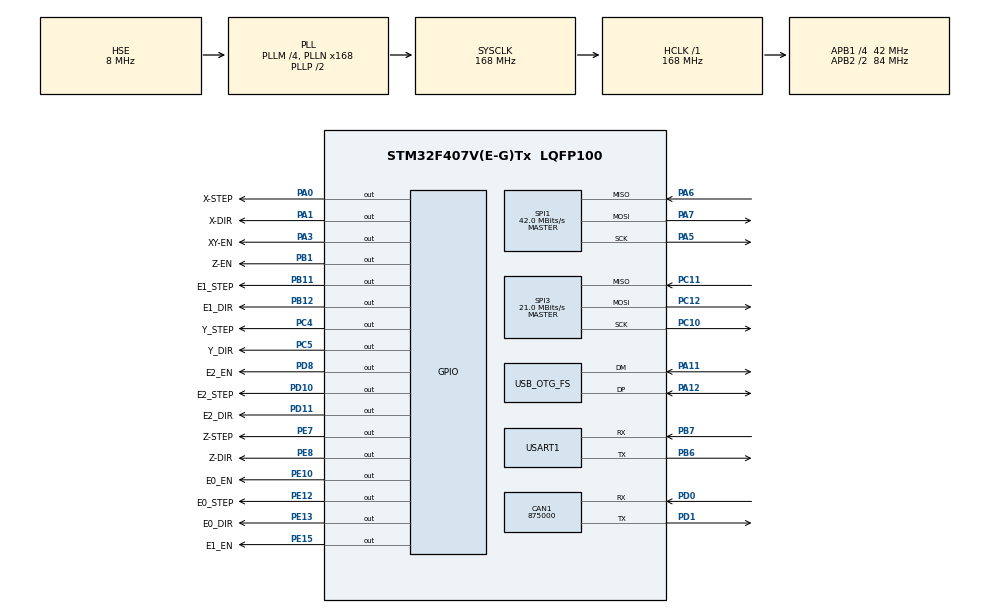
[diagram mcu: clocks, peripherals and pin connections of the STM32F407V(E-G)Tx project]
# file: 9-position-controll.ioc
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CAN1.CalculateBaudRate=875000
CAN1.CalculateTimeBit=1142
CAN1.CalculateTimeQuantum=380.95238095238096
Mcu.Family=STM32F4
Mcu.Name=STM32F407V(E-G)Tx
Mcu.Package=LQFP100
NVIC.OTG_FS_IRQn=true\:0\:0\:false\:false\:true\:true\:true\:true
NVIC.PriorityGroup=NVIC_PRIORITYGROUP_4
NVIC.TIM2_IRQn=true\:0\:0\:false\:false\:true\:true\:true\:true
NVIC.USART1_IRQn=true\:0\:0\:false\:false\:true\:true\:true\:true
PA0-WKUP.GPIO_Label=X-STEP
PA0-WKUP.PinState=GPIO_PIN_RESET
PA0-WKUP.Signal=GPIO_Output
PA1.GPIO_Label=X-DIR
PA1.GPIO_ModeDefaultOutputPP=GPIO_MODE_OUTPUT_PP
PA1.PinState=GPIO_PIN_RESET
PA1.Signal=GPIO_Output
PA11.GPIO_Mode=GPIO_MODE_AF_PP
PA11.Mode=Device_Only
PA11.Signal=USB_OTG_FS_DM
PA12.GPIO_Mode=GPIO_MODE_AF_PP
PA12.Mode=Device_Only
PA12.Signal=USB_OTG_FS_DP
PA13.Mode=Serial_Wire
PA13.Signal=SYS_JTMS-SWDIO
PA14.Mode=Serial_Wire
PA14.Signal=SYS_JTCK-SWCLK
PA3.GPIO_Label=XY-EN
PA3.Signal=GPIO_Output
PA5.Mode=Full_Duplex_Master
PA5.Signal=SPI1_SCK
PA6.Mode=Full_Duplex_Master
PA6.Signal=SPI1_MISO
PA7.Mode=Full_Duplex_Master
PA7.Signal=SPI1_MOSI
PB1.GPIO_Label=Z-EN
PB1.PinState=GPIO_PIN_RESET
PB1.Signal=GPIO_Output
PB11.GPIO_Label=E1_STEP
PB11.Signal=GPIO_Output
PB12.GPIO_Label=E1_DIR
PB12.Signal=GPIO_Output
PB6.GPIO_ModeDefaultPP=GPIO_MODE_AF_PP
PB6.Mode=Asynchronous
PB6.Signal=USART1_TX
PB7.GPIO_ModeDefaultPP=GPIO_MODE_AF_PP
PB7.Mode=Asynchronous
PB7.Signal=USART1_RX
PC10.Mode=Full_Duplex_Master
PC10.Signal=SPI3_SCK
PC11.Mode=Full_Duplex_Master
PC11.Signal=SPI3_MISO
PC12.Mode=Full_Duplex_Master
PC12.Signal=SPI3_MOSI
PC4.GPIO_Label=Y_STEP
PC4.Signal=GPIO_Output
PC5.GPIO_Label=Y_DIR
PC5.Signal=GPIO_Output
PD0.Mode=CAN_Activate
PD0.Signal=CAN1_RX
PD1.Mode=CAN_Activate
PD1.Signal=CAN1_TX
PD10.GPIO_Label=E2_STEP
PD10.Signal=GPIO_Output
PD11.GPIO_Label=E2_DIR
PD11.Signal=GPIO_Output
PD8.GPIO_Label=E2_EN
PD8.Signal=GPIO_Output
PE10.GPIO_Label=E0_EN
PE10.Signal=GPIO_Output
PE12.GPIO_Label=E0_STEP
PE12.Signal=GPIO_Output
PE13.GPIO_Label=E0_DIR
PE13.Signal=GPIO_Output
PE15.GPIO_Label=E1_EN
PE15.Signal=GPIO_Output
PE7.GPIO_Label=Z-STEP
PE7.PinState=GPIO_PIN_RESET
PE7.Signal=GPIO_Output
PE8.GPIO_Label=Z-DIR
PE8.PinState=GPIO_PIN_RESET
PE8.Signal=GPIO_Output
PH0-OSC_IN.Mode=HSE-External-Oscillator
PH0-OSC_IN.Signal=RCC_OSC_IN
PH1-OSC_OUT.Mode=HSE-External-Oscillator
PH1-OSC_OUT.Signal=RCC_OSC_OUT
ProjectManager.HeapSize=0x600
ProjectManager.StackSize=0x600
ProjectManager.TargetToolchain=MDK-ARM V5.32
RCC.48MHZClocksFreq_Value=48000000
RCC.AHBFreq_Value=168000000
RCC.APB1CLKDivider=RCC_HCLK_DIV4
RCC.APB1Freq_Value=42000000
RCC.APB1TimFreq_Value=84000000
RCC.APB2CLKDivider=RCC_HCLK_DIV2
RCC.APB2Freq_Value=84000000
RCC.APB2TimFreq_Value=168000000
RCC.CortexFreq_Value=168000000
RCC.HCLKFreq_Value=168000000
RCC.HSE_VALUE=8000000
RCC.HSI_VALUE=16000000
RCC.LSE_VALUE=32768
RCC.PLLM=4
RCC.PLLN=168
RCC.PLLQ=7
RCC.SYSCLKFreq_VALUE=168000000
RCC.SYSCLKSource=RCC_SYSCLKSOURCE_PLLCLK
RCC.VCOOutputFreq_Value=336000000
SPI1.CalculateBaudRate=42.0 MBits/s
SPI1.Direction=SPI_DIRECTION_2LINES
SPI1.Mode=SPI_MODE_MASTER
SPI1.VirtualType=VM_MASTER
SPI3.CalculateBaudRate=21.0 MBits/s
SPI3.Direction=SPI_DIRECTION_2LINES
SPI3.Mode=SPI_MODE_MASTER
SPI3.VirtualType=VM_MASTER
TIM2.Prescaler=84
USART1.VirtualMode=VM_ASYNC
USB_DEVICE.CLASS_NAME_FS=CDC
USB_DEVICE.VirtualMode-CDC_FS=Cdc
USB_DEVICE.VirtualModeFS=Cdc_FS
USB_OTG_FS.VirtualMode=Device_Only
VP_TIM2_VS_ClockSourceINT.Mode=Internal
VP_USB_DEVICE_VS_USB_DEVICE_CDC_FS.Mode=CDC_FS
board=custom

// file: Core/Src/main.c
/* USER CODE BEGIN Header */
/**
  ******************************************************************************
  * @file           : main.c
  * @brief          : Main program body
  ******************************************************************************
  * @attention
  *
  * Copyright (c) 2026 STMicroelectronics.
  * All rights reserved.
  *
  * This software is licensed under terms that can be found in the LICENSE file
  * in the root directory of this software component.
  * If no LICENSE file comes with this software, it is provided AS-IS.
  *
  ******************************************************************************
  */
/* USER CODE END Header */
#include "main.h"
#include "usb_device.h"

/* USER CODE BEGIN Includes */
#include "uart_usb_bridge.h"
#include "position-controll.h"
#include "StepperDriver.h"
#include "StepperEngine.h"
#include "Queue.h"

/* USER CODE END Includes */

CAN_HandleTypeDef hcan1;

SPI_HandleTypeDef hspi1;
SPI_HandleTypeDef hspi3;

TIM_HandleTypeDef htim2;

UART_HandleTypeDef huart1;

void SystemClock_Config(void);
static void MX_GPIO_Init(void);
static void MX_USART1_UART_Init(void);
static void MX_TIM2_Init(void);
static void MX_CAN1_Init(void);
static void MX_SPI1_Init(void);
static void MX_SPI3_Init(void);

int main(void)
{

  /* MCU Configuration--------------------------------------------------------*/

  /* Reset of all peripherals, Initializes the Flash interface and the Systick. */
  HAL_Init();

  /* Configure the system clock */
  SystemClock_Config();

  /* Initialize all configured peripherals */
  MX_GPIO_Init();
  MX_USB_DEVICE_Init();
  MX_USART1_UART_Init();
  MX_TIM2_Init();
  MX_CAN1_Init();
  MX_SPI1_Init();
  MX_SPI3_Init();
  /* USER CODE BEGIN 2 */

	HAL_TIM_Base_Start_IT(&htim2);

	setvbuf(stdout, NULL, _IONBF, 0);

	UART_USB_Bridge_Task_Init();

	HAL_Delay(1000);

	printf("init sucssesfull .\n");

  /* USER CODE END 2 */

  /* Infinite loop */
  /* USER CODE BEGIN WHILE */

  while (1)
  {
		My_App();

		UART_USB_Bridge_Task();
		Stepper_PID_Task();
		Stepper_ISR();

    /* USER CODE END WHILE */

  }
}

void SystemClock_Config(void)
{
  RCC_OscInitTypeDef RCC_OscInitStruct = {0};
  RCC_ClkInitTypeDef RCC_ClkInitStruct = {0};

  /** Configure the main internal regulator output voltage
  */
  __HAL_RCC_PWR_CLK_ENABLE();
  __HAL_PWR_VOLTAGESCALING_CONFIG(PWR_REGULATOR_VOLTAGE_SCALE1);

  /** Initializes the RCC Oscillators according to the specified parameters
  * in the RCC_OscInitTypeDef structure.
  */
  RCC_OscInitStruct.OscillatorType = RCC_OSCILLATORTYPE_HSE;
  RCC_OscInitStruct.HSEState = RCC_HSE_ON;
  RCC_OscInitStruct.PLL.PLLState = RCC_PLL_ON;
  RCC_OscInitStruct.PLL.PLLSource = RCC_PLLSOURCE_HSE;
  RCC_OscInitStruct.PLL.PLLM = 4;
  RCC_OscInitStruct.PLL.PLLN = 168;
  RCC_OscInitStruct.PLL.PLLP = RCC_PLLP_DIV2;
  RCC_OscInitStruct.PLL.PLLQ = 7;
  if (HAL_RCC_OscConfig(&RCC_OscInitStruct) != HAL_OK)
  {
    Error_Handler();
  }

  /** Initializes the CPU, AHB and APB buses clocks
  */
  RCC_ClkInitStruct.ClockType = RCC_CLOCKTYPE_HCLK|RCC_CLOCKTYPE_SYSCLK
                              |RCC_CLOCKTYPE_PCLK1|RCC_CLOCKTYPE_PCLK2;
  RCC_ClkInitStruct.SYSCLKSource = RCC_SYSCLKSOURCE_PLLCLK;
  RCC_ClkInitStruct.AHBCLKDivider = RCC_SYSCLK_DIV1;
  RCC_ClkInitStruct.APB1CLKDivider = RCC_HCLK_DIV4;
  RCC_ClkInitStruct.APB2CLKDivider = RCC_HCLK_DIV2;

  if (HAL_RCC_ClockConfig(&RCC_ClkInitStruct, FLASH_LATENCY_5) != HAL_OK)
  {
    Error_Handler();
  }
}

static void MX_CAN1_Init(void)
{

  hcan1.Instance = CAN1;
  hcan1.Init.Prescaler = 16;
  hcan1.Init.Mode = CAN_MODE_NORMAL;
  hcan1.Init.SyncJumpWidth = CAN_SJW_1TQ;
  hcan1.Init.TimeSeg1 = CAN_BS1_1TQ;
  hcan1.Init.TimeSeg2 = CAN_BS2_1TQ;
  hcan1.Init.TimeTriggeredMode = DISABLE;
  hcan1.Init.AutoBusOff = DISABLE;
  hcan1.Init.AutoWakeUp = DISABLE;
  hcan1.Init.AutoRetransmission = DISABLE;
  hcan1.Init.ReceiveFifoLocked = DISABLE;
  hcan1.Init.TransmitFifoPriority = DISABLE;
  if (HAL_CAN_Init(&hcan1) != HAL_OK)
  {
    Error_Handler();
  }

}

static void MX_SPI1_Init(void)
{

  /* SPI1 parameter configuration*/
  hspi1.Instance = SPI1;
  hspi1.Init.Mode = SPI_MODE_MASTER;
  hspi1.Init.Direction = SPI_DIRECTION_2LINES;
  hspi1.Init.DataSize = SPI_DATASIZE_8BIT;
  hspi1.Init.CLKPolarity = SPI_POLARITY_LOW;
  hspi1.Init.CLKPhase = SPI_PHASE_1EDGE;
  hspi1.Init.NSS = SPI_NSS_SOFT;
  hspi1.Init.BaudRatePrescaler = SPI_BAUDRATEPRESCALER_2;
  hspi1.Init.FirstBit = SPI_FIRSTBIT_MSB;
  hspi1.Init.TIMode = SPI_TIMODE_DISABLE;
  hspi1.Init.CRCCalculation = SPI_CRCCALCULATION_DISABLE;
  hspi1.Init.CRCPolynomial = 10;
  if (HAL_SPI_Init(&hspi1) != HAL_OK)
  {
    Error_Handler();
  }

}

static void MX_SPI3_Init(void)
{

  /* SPI3 parameter configuration*/
  hspi3.Instance = SPI3;
  hspi3.Init.Mode = SPI_MODE_MASTER;
  hspi3.Init.Direction = SPI_DIRECTION_2LINES;
  hspi3.Init.DataSize = SPI_DATASIZE_8BIT;
  hspi3.Init.CLKPolarity = SPI_POLARITY_LOW;
  hspi3.Init.CLKPhase = SPI_PHASE_1EDGE;
  hspi3.Init.NSS = SPI_NSS_SOFT;
  hspi3.Init.BaudRatePrescaler = SPI_BAUDRATEPRESCALER_2;
  hspi3.Init.FirstBit = SPI_FIRSTBIT_MSB;
  hspi3.Init.TIMode = SPI_TIMODE_DISABLE;
  hspi3.Init.CRCCalculation = SPI_CRCCALCULATION_DISABLE;
  hspi3.Init.CRCPolynomial = 10;
  if (HAL_SPI_Init(&hspi3) != HAL_OK)
  {
    Error_Handler();
  }

}

static void MX_TIM2_Init(void)
{

  TIM_ClockConfigTypeDef sClockSourceConfig = {0};
  TIM_MasterConfigTypeDef sMasterConfig = {0};

  htim2.Instance = TIM2;
  htim2.Init.Prescaler = 84;
  htim2.Init.CounterMode = TIM_COUNTERMODE_UP;
  htim2.Init.Period = 4294967295;
  htim2.Init.ClockDivision = TIM_CLOCKDIVISION_DIV1;
  htim2.Init.AutoReloadPreload = TIM_AUTORELOAD_PRELOAD_DISABLE;
  if (HAL_TIM_Base_Init(&htim2) != HAL_OK)
  {
    Error_Handler();
  }
  sClockSourceConfig.ClockSource = TIM_CLOCKSOURCE_INTERNAL;
  if (HAL_TIM_ConfigClockSource(&htim2, &sClockSourceConfig) != HAL_OK)
  {
    Error_Handler();
  }
  sMasterConfig.MasterOutputTrigger = TIM_TRGO_RESET;
  sMasterConfig.MasterSlaveMode = TIM_MASTERSLAVEMODE_DISABLE;
  if (HAL_TIMEx_MasterConfigSynchronization(&htim2, &sMasterConfig) != HAL_OK)
  {
    Error_Handler();
  }

}

static void MX_USART1_UART_Init(void)
{

  huart1.Instance = USART1;
  huart1.Init.BaudRate = 115200;
  huart1.Init.WordLength = UART_WORDLENGTH_8B;
  huart1.Init.StopBits = UART_STOPBITS_1;
  huart1.Init.Parity = UART_PARITY_NONE;
  huart1.Init.Mode = UART_MODE_TX_RX;
  huart1.Init.HwFlowCtl = UART_HWCONTROL_NONE;
  huart1.Init.OverSampling = UART_OVERSAMPLING_16;
  if (HAL_UART_Init(&huart1) != HAL_OK)
  {
    Error_Handler();
  }

}

static void MX_GPIO_Init(void)
{
  GPIO_InitTypeDef GPIO_InitStruct = {0};

  /* GPIO Ports Clock Enable */
  __HAL_RCC_GPIOE_CLK_ENABLE();
  __HAL_RCC_GPIOC_CLK_ENABLE();
  __HAL_RCC_GPIOH_CLK_ENABLE();
  __HAL_RCC_GPIOA_CLK_ENABLE();
  __HAL_RCC_GPIOB_CLK_ENABLE();
  __HAL_RCC_GPIOD_CLK_ENABLE();

  /*Configure GPIO pin Output Level */
  HAL_GPIO_WritePin(GPIOA, X_STEP_Pin|X_DIR_Pin|XY_EN_Pin, GPIO_PIN_RESET);

  /*Configure GPIO pin Output Level */
  HAL_GPIO_WritePin(GPIOC, Y_STEP_Pin|Y_DIR_Pin, GPIO_PIN_RESET);

  /*Configure GPIO pin Output Level */
  HAL_GPIO_WritePin(GPIOB, Z_EN_Pin|E1_STEP_Pin|E1_DIR_Pin, GPIO_PIN_RESET);

  /*Configure GPIO pin Output Level */
  HAL_GPIO_WritePin(GPIOE, Z_STEP_Pin|Z_DIR_Pin|E0_EN_Pin|E0_STEP_Pin
                          |E0_DIR_Pin|E1_EN_Pin, GPIO_PIN_RESET);

  /*Configure GPIO pin Output Level */
  HAL_GPIO_WritePin(GPIOD, E2_EN_Pin|E2_STEP_Pin|E2_DIR_Pin, GPIO_PIN_RESET);

  /*Configure GPIO pins : PE2 PE3 PE4 PE5
                           PE6 PE9 PE11 PE14
                           PE0 PE1 */
  GPIO_InitStruct.Pin = GPIO_PIN_2|GPIO_PIN_3|GPIO_PIN_4|GPIO_PIN_5
                          |GPIO_PIN_6|GPIO_PIN_9|GPIO_PIN_11|GPIO_PIN_14
                          |GPIO_PIN_0|GPIO_PIN_1;
  GPIO_InitStruct.Mode = GPIO_MODE_ANALOG;
  GPIO_InitStruct.Pull = GPIO_NOPULL;
  HAL_GPIO_Init(GPIOE, &GPIO_InitStruct);

  /*Configure GPIO pins : PC13 PC14 PC15 PC0
                           PC1 PC2 PC3 PC6
                           PC7 PC8 PC9 */
  GPIO_InitStruct.Pin = GPIO_PIN_13|GPIO_PIN_14|GPIO_PIN_15|GPIO_PIN_0
                          |GPIO_PIN_1|GPIO_PIN_2|GPIO_PIN_3|GPIO_PIN_6
                          |GPIO_PIN_7|GPIO_PIN_8|GPIO_PIN_9;
  GPIO_InitStruct.Mode = GPIO_MODE_ANALOG;
  GPIO_InitStruct.Pull = GPIO_NOPULL;
  HAL_GPIO_Init(GPIOC, &GPIO_InitStruct);

  /*Configure GPIO pins : X_STEP_Pin X_DIR_Pin XY_EN_Pin */
  GPIO_InitStruct.Pin = X_STEP_Pin|X_DIR_Pin|XY_EN_Pin;
  GPIO_InitStruct.Mode = GPIO_MODE_OUTPUT_PP;
  GPIO_InitStruct.Pull = GPIO_NOPULL;
  GPIO_InitStruct.Speed = GPIO_SPEED_FREQ_LOW;
  HAL_GPIO_Init(GPIOA, &GPIO_InitStruct);

  /*Configure GPIO pins : PA2 PA4 PA8 PA9
                           PA10 PA15 */
  GPIO_InitStruct.Pin = GPIO_PIN_2|GPIO_PIN_4|GPIO_PIN_8|GPIO_PIN_9
                          |GPIO_PIN_10|GPIO_PIN_15;
  GPIO_InitStruct.Mode = GPIO_MODE_ANALOG;
  GPIO_InitStruct.Pull = GPIO_NOPULL;
  HAL_GPIO_Init(GPIOA, &GPIO_InitStruct);

  /*Configure GPIO pins : Y_STEP_Pin Y_DIR_Pin */
  GPIO_InitStruct.Pin = Y_STEP_Pin|Y_DIR_Pin;
  GPIO_InitStruct.Mode = GPIO_MODE_OUTPUT_PP;
  GPIO_InitStruct.Pull = GPIO_NOPULL;
  GPIO_InitStruct.Speed = GPIO_SPEED_FREQ_LOW;
  HAL_GPIO_Init(GPIOC, &GPIO_InitStruct);

  /*Configure GPIO pins : PB0 PB2 PB10 PB13
                           PB14 PB15 PB3 PB4
                           PB5 PB8 PB9 */
  GPIO_InitStruct.Pin = GPIO_PIN_0|GPIO_PIN_2|GPIO_PIN_10|GPIO_PIN_13
                          |GPIO_PIN_14|GPIO_PIN_15|GPIO_PIN_3|GPIO_PIN_4
                          |GPIO_PIN_5|GPIO_PIN_8|GPIO_PIN_9;
  GPIO_InitStruct.Mode = GPIO_MODE_ANALOG;
  GPIO_InitStruct.Pull = GPIO_NOPULL;
  HAL_GPIO_Init(GPIOB, &GPIO_InitStruct);

  /*Configure GPIO pins : Z_EN_Pin E1_STEP_Pin E1_DIR_Pin */
  GPIO_InitStruct.Pin = Z_EN_Pin|E1_STEP_Pin|E1_DIR_Pin;
  GPIO_InitStruct.Mode = GPIO_MODE_OUTPUT_PP;
  GPIO_InitStruct.Pull = GPIO_NOPULL;
  GPIO_InitStruct.Speed = GPIO_SPEED_FREQ_LOW;
  HAL_GPIO_Init(GPIOB, &GPIO_InitStruct);

  /*Configure GPIO pins : Z_STEP_Pin Z_DIR_Pin E0_EN_Pin E0_STEP_Pin
                           E0_DIR_Pin E1_EN_Pin */
  GPIO_InitStruct.Pin = Z_STEP_Pin|Z_DIR_Pin|E0_EN_Pin|E0_STEP_Pin
                          |E0_DIR_Pin|E1_EN_Pin;
  GPIO_InitStruct.Mode = GPIO_MODE_OUTPUT_PP;
  GPIO_InitStruct.Pull = GPIO_NOPULL;
  GPIO_InitStruct.Speed = GPIO_SPEED_FREQ_LOW;
  HAL_GPIO_Init(GPIOE, &GPIO_InitStruct);

  /*Configure GPIO pins : E2_EN_Pin E2_STEP_Pin E2_DIR_Pin */
  GPIO_InitStruct.Pin = E2_EN_Pin|E2_STEP_Pin|E2_DIR_Pin;
  GPIO_InitStruct.Mode = GPIO_MODE_OUTPUT_PP;
  GPIO_InitStruct.Pull = GPIO_NOPULL;
  GPIO_InitStruct.Speed = GPIO_SPEED_FREQ_LOW;
  HAL_GPIO_Init(GPIOD, &GPIO_InitStruct);

  /*Configure GPIO pins : PD9 PD12 PD13 PD14
                           PD15 PD2 PD3 PD4
                           PD5 PD6 PD7 */
  GPIO_InitStruct.Pin = GPIO_PIN_9|GPIO_PIN_12|GPIO_PIN_13|GPIO_PIN_14
                          |GPIO_PIN_15|GPIO_PIN_2|GPIO_PIN_3|GPIO_PIN_4
                          |GPIO_PIN_5|GPIO_PIN_6|GPIO_PIN_7;
  GPIO_InitStruct.Mode = GPIO_MODE_ANALOG;
  GPIO_InitStruct.Pull = GPIO_NOPULL;
  HAL_GPIO_Init(GPIOD, &GPIO_InitStruct);

}

void Error_Handler(void)
{
  __disable_irq();
  while (1)
  {
  }
}
